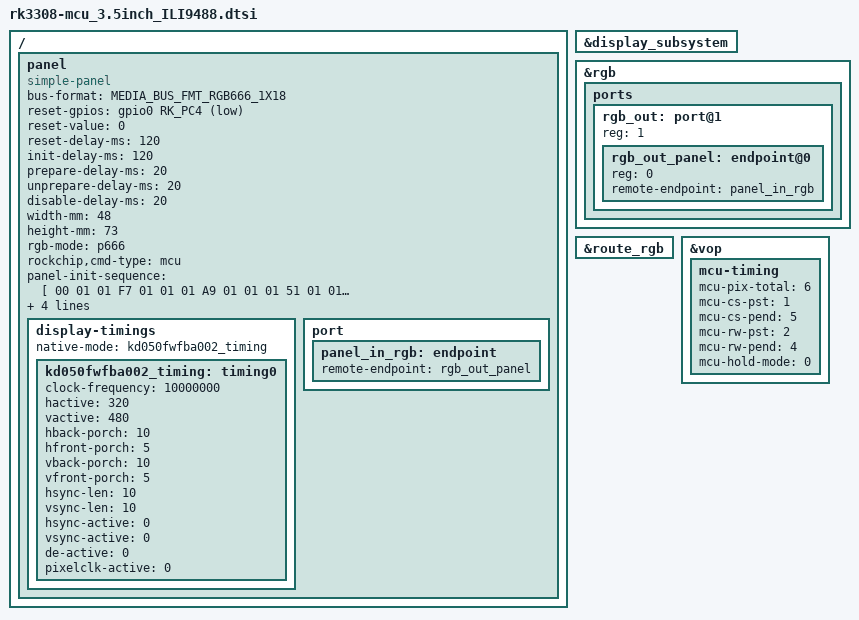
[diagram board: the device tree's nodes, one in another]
/*
 * Copyright (c) 2018 Fuzhou Rockchip Electronics Co., Ltd
 *
 * SPDX-License-Identifier: (GPL-2.0+ OR MIT)
 */

/ {

panel: panel {
		compatible = "simple-panel";
		bus-format = <MEDIA_BUS_FMT_RGB666_1X18>;
		//backlight = <&backlight>;
		//enable-gpios = <&gpio0 RK_PA4 GPIO_ACTIVE_LOW>;
		//enable-delay-ms = <20>;
		reset-gpios = <&gpio0 RK_PC4 GPIO_ACTIVE_LOW>;
		reset-value = <0>;
		reset-delay-ms = <120>;
		init-delay-ms = <120>;
		prepare-delay-ms = <20>;
		unprepare-delay-ms = <20>;
		disable-delay-ms = <20>;
		width-mm = <48>;
		height-mm = <73>;
		rgb-mode = "p666";
		status = "okay";
		rockchip,cmd-type = "mcu";

		/* type:0 is cmd, 1 is data */
		panel-init-sequence = [
			/* type delay num val1 val2 val3 */
            00   01  01  F7
            01   01  01  A9
            01   01  01  51
            01   01  01  2C
            01   01  01  82

            00   01  01  C0
            01   01  01  11
            01   01  01  09

            00   01  01  C1
            01   01  01  41

            00   01  01  C5
            01   01  01  00
            01   01  01  0A
            01   01  01  80

            00   01  01  B1
            01   01  01  B0
            01   01  01  11

            00   01  01  B4
            01   01  01  02
            00   01  01  B6
            01   01  01  02
            01   01  01  22

            00   01  01  B7
            01   01  01  c6

            00   01  01  BE
            01   01  01  00
            01   01  01  04

            00   01  01  E9
            01   01  01  00

            00   01  01  36
            01   01  01  08

            00   01  01  3A
            01   01  01  66

            00   01  01  E0
            01   01  01  00
            01   01  01  07
            01   01  01  10
            01   01  01  09
            01   01  01  17
            01   01  01  0B
            01   01  01  41
            01   01  01  89
            01   01  01  4B
            01   01  01  0A
            01   01  01  0C
            01   01  01  0E
            01   01  01  18
            01   01  01  1B
            01   01  01  0F

            00   01  01  E1
            01   01  01  00
            01   01  01  17
            01   01  01  1A
            01   01  01  04
            01   01  01  0E
            01   01  01  06
            01   01  01  2F
            01   01  01  45
            01   01  01  43
            01   01  01  02
            01   01  01  0A
            01   01  01  09
            01   01  01  32
            01   01  01  36
            01   01  01  0F

            00   78  01  11
            00   00  01  29

            /*00   01  01  2A
            01   01  01  00
            01   01  01  00
            01   01  01  01
            01   01  01  DF

            00   01  01  2B
            01   01  01  00
            01   01  01  00
            01   01  01  01
            01   01  01  3F*/

            00   01  01  2C
		];

		panel-exit-sequence = [
			/* type delay num val1 val2 val3 */
			00   0a  01  28
			00   78  01  10
		];

        panel-color-sequence = [
            01  00  01  0F
            01  00  01  00
       ];

		display-timings {
			native-mode = <&kd050fwfba002_timing>;

			kd050fwfba002_timing: timing0 {
				clock-frequency = <10000000>;
				hactive = <320>;
				vactive = <480>;
				hback-porch = <10>;
				hfront-porch = <5>;
				vback-porch = <10>;
				vfront-porch = <5>;
				hsync-len = <10>;
				vsync-len = <10>;
				hsync-active = <0>;
				vsync-active = <0>;
				de-active = <0>;
				pixelclk-active = <0>;
			};
		};

		port {
			panel_in_rgb: endpoint {
				remote-endpoint = <&rgb_out_panel>;
			};
		};
	};
};

&display_subsystem {
    status = "okay";
};

&rgb {
    status = "okay";

    ports {
        rgb_out: port@1 {
            reg = <1>;
            #address-cells = <1>;
            #size-cells = <0>;

            rgb_out_panel: endpoint@0 {
                reg = <0>;
                remote-endpoint = <&panel_in_rgb>;
                           };
                 };
    };
};

&route_rgb {
    status = "okay";
};

&vop {
    status = "okay";

    mcu-timing {
        mcu-pix-total = <6>;
        mcu-cs-pst = <1>;
        mcu-cs-pend = <5>;
        mcu-rw-pst = <2>; 
        mcu-rw-pend = <4>;

        mcu-hold-mode = <0>;
    };                    

};
